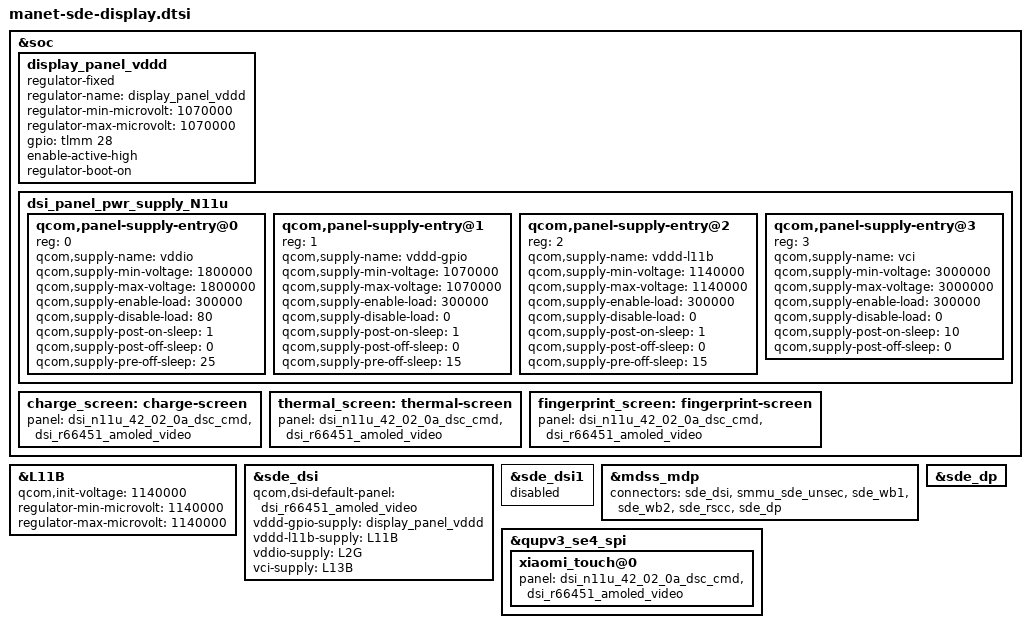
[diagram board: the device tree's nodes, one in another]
#include "pineapple-sde-display.dtsi"
#include "dsi-panel-n11u-42-02-0a-dsc-cmd.dtsi"
#include "dsi-panel-r66451-dsc-fhd-plus-video.dtsi"


&soc {
	display_panel_vddd: display_panel_vddd {
		compatible = "regulator-fixed";
		regulator-name = "display_panel_vddd";
		regulator-min-microvolt = <1070000>;
		regulator-max-microvolt = <1070000>;
		gpio = <&tlmm 28 0>;
		enable-active-high;
		regulator-boot-on;
    };

	dsi_panel_pwr_supply_N11u: dsi_panel_pwr_supply_N11u {
		qcom,panel-supply-entry@0 {
			reg = <0>;
			qcom,supply-name = "vddio";
			qcom,supply-min-voltage = <1800000>;
			qcom,supply-max-voltage = <1800000>;
			qcom,supply-enable-load = <300000>;
			qcom,supply-disable-load = <80>;
			qcom,supply-post-on-sleep = <1>;
			qcom,supply-post-off-sleep = <0>;
			qcom,supply-pre-off-sleep = <25>;
		};
		qcom,panel-supply-entry@1 {
			reg = <1>;
			qcom,supply-name = "vddd-gpio";
			qcom,supply-min-voltage = <1070000>;
			qcom,supply-max-voltage = <1070000>;
			qcom,supply-enable-load = <300000>;
			qcom,supply-disable-load = <0>;
			qcom,supply-post-on-sleep = <1>;
			qcom,supply-post-off-sleep = <0>;
			qcom,supply-pre-off-sleep = <15>;
		};
		qcom,panel-supply-entry@2 {
			reg = <2>;
			qcom,supply-name = "vddd-l11b";
			qcom,supply-min-voltage = <1140000>;
			qcom,supply-max-voltage = <1140000>;
			qcom,supply-enable-load = <300000>;
			qcom,supply-disable-load = <0>;
			qcom,supply-post-on-sleep = <1>;
			qcom,supply-post-off-sleep = <0>;
			qcom,supply-pre-off-sleep = <15>;
		};
		qcom,panel-supply-entry@3 {
			reg = <3>;
			qcom,supply-name = "vci";
			qcom,supply-min-voltage = <3000000>;
			qcom,supply-max-voltage = <3000000>;
			qcom,supply-enable-load = <300000>;
			qcom,supply-disable-load = <0>;
			qcom,supply-post-on-sleep = <10>;
			qcom,supply-post-off-sleep = <0>;
		};
	};
};

&L11B {
	qcom,init-voltage = <1140000>;
	regulator-min-microvolt = <1140000>;
	regulator-max-microvolt = <1140000>;
};

&sde_dsi {
	qcom,dsi-default-panel = <&dsi_r66451_amoled_video>;
	vddd-gpio-supply = <&display_panel_vddd>;
	vddd-l11b-supply = <&L11B>;
	vddio-supply = <&L2G>;
	vci-supply = <&L13B>;
};

&sde_dsi1 {
	status = "disabled";
};

&mdss_mdp {
	connectors = <&sde_dsi &smmu_sde_unsec &sde_wb1 &sde_wb2 &sde_rscc &sde_dp>;
};

&sde_dp {
	status = "ok";
};

&qupv3_se4_spi {
	xiaomi_touch@0 {
		panel = <&dsi_n11u_42_02_0a_dsc_cmd
			&dsi_r66451_amoled_video>;
	};
};

&soc {
	charge_screen: charge-screen {
		panel  = <&dsi_n11u_42_02_0a_dsc_cmd
			&dsi_r66451_amoled_video>;
	};
};

&soc {
	thermal_screen: thermal-screen {
		panel = <&dsi_n11u_42_02_0a_dsc_cmd
			&dsi_r66451_amoled_video>;
	};
	fingerprint_screen: fingerprint-screen {
		panel = <&dsi_n11u_42_02_0a_dsc_cmd
			&dsi_r66451_amoled_video>;
	};
};
